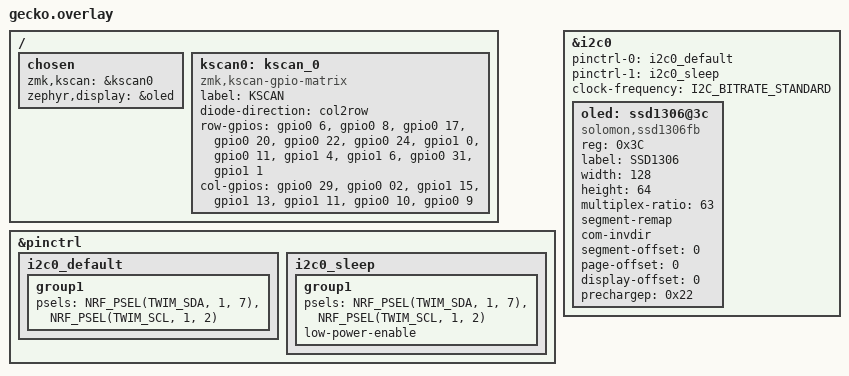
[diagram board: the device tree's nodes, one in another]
/ {
    chosen {
        zmk,kscan = &kscan0;
        zephyr,display = &oled;
    };

    kscan0: kscan_0 {
        compatible = "zmk,kscan-gpio-matrix";
        label = "KSCAN";
        diode-direction = "col2row";

        row-gpios
            = <&gpio0 6 (GPIO_ACTIVE_HIGH | GPIO_PULL_DOWN)> // ROW 0
            , <&gpio0 8 (GPIO_ACTIVE_HIGH | GPIO_PULL_DOWN)> // ROW 1
            , <&gpio0 17 (GPIO_ACTIVE_HIGH | GPIO_PULL_DOWN)> // ROW 2
            , <&gpio0 20 (GPIO_ACTIVE_HIGH | GPIO_PULL_DOWN)> // ROW 3
            , <&gpio0 22 (GPIO_ACTIVE_HIGH | GPIO_PULL_DOWN)> // ROW 4
            , <&gpio0 24 (GPIO_ACTIVE_HIGH | GPIO_PULL_DOWN)> // ROW 5
            , <&gpio1 0 (GPIO_ACTIVE_HIGH | GPIO_PULL_DOWN)> // ROW 6
            , <&gpio0 11 (GPIO_ACTIVE_HIGH | GPIO_PULL_DOWN)> // ROW 7
            , <&gpio1 4 (GPIO_ACTIVE_HIGH | GPIO_PULL_DOWN)> // ROW 8
            , <&gpio1 6 (GPIO_ACTIVE_HIGH | GPIO_PULL_DOWN)> // ROW 9
            , <&gpio0 31 (GPIO_ACTIVE_HIGH | GPIO_PULL_DOWN)> // ROW 10
            , <&gpio1 1 (GPIO_ACTIVE_HIGH | GPIO_PULL_DOWN)> // ROW 11
            ;

        col-gpios
            = <&gpio0 29 GPIO_ACTIVE_HIGH>
            , <&gpio0 02 GPIO_ACTIVE_HIGH>
            , <&gpio1 15 GPIO_ACTIVE_HIGH>
            , <&gpio1 13 GPIO_ACTIVE_HIGH>
            , <&gpio1 11 GPIO_ACTIVE_HIGH>
            , <&gpio0 10 GPIO_ACTIVE_HIGH>
            , <&gpio0 9 GPIO_ACTIVE_HIGH>
            ;
    };
};
&pinctrl {
    i2c0_default: i2c0_default {
        group1 {
            psels = <NRF_PSEL(TWIM_SDA, 1, 7)>,   /* SDA = P1.07 */
                    <NRF_PSEL(TWIM_SCL, 1, 2)>;   /* SCL = P1.02 */
            /* optional: bias-pull-up; */
        };
    };

    i2c0_sleep: i2c0_sleep {
        group1 {
            psels = <NRF_PSEL(TWIM_SDA, 1, 7)>,
                    <NRF_PSEL(TWIM_SCL, 1, 2)>;
            low-power-enable;
        };
    };
};

&i2c0 {
    status = "okay";
    pinctrl-0 = <&i2c0_default>;
    pinctrl-1 = <&i2c0_sleep>;
    pinctrl-names = "default", "sleep";
    clock-frequency = <I2C_BITRATE_STANDARD>;

    oled: ssd1306@3c {
        compatible = "solomon,ssd1306fb";
        reg = <0x3C>;      /* 0x3D if you flip the addr switch */
        label = "SSD1306";
        width = <128>;
        height = <64>;
        multiplex-ratio = <63>;
        segment-remap;
        com-invdir;
        segment-offset = <0>;
        page-offset = <0>;
        display-offset = <0>;
        prechargep = <0x22>;       /* required by your Zephyr binding */
        status = "okay";
    };
};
